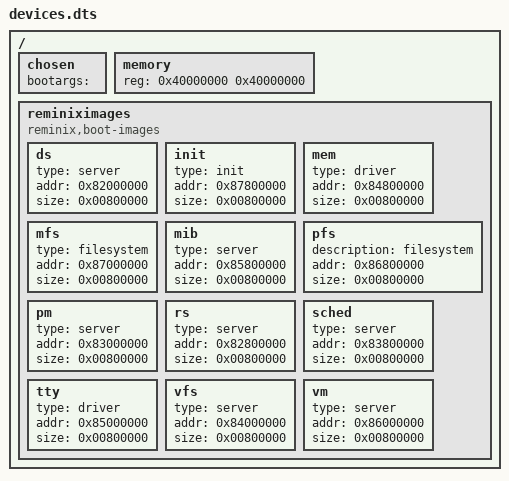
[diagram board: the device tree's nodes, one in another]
/dts-v1/;

#include "sun8i-h3-orangepi-pc-plus.dts"

/ {

	chosen {
		bootargs = "";
	};

	memory {
		device_type = "memory";
		reg = <0x40000000 0x40000000>;
	};

	reminiximages {
		compatible = "reminix,boot-images";
    		  ds {
				  type = "server";
                  addr = <0x82000000>;
                  size = <0x00800000>;
            };

    		  init {
				  type = "init";
                  addr = <0x87800000>;
                  size = <0x00800000>;
            };

    		  mem {
				  type = "driver";
                  addr = <0x84800000>;
				  size = <0x00800000>;
            };

    		  mfs {
				  type = "filesystem";
                  addr = <0x87000000>;
				  size = <0x00800000>;
            };

    		  mib {
				  type = "server";
                  addr = <0x85800000>;
				  size = <0x00800000>;
            };

    		  pfs {
            			description = "filesystem";
                  addr = <0x86800000>;
				  size = <0x00800000>;
            };

    		  pm {
				  type = "server";
                  addr = <0x83000000>;
				  size = <0x00800000>;
            };

    		  rs {
				  type = "server";
                  addr = <0x82800000>;
				  size = <0x00800000>;
            };

    		  sched {
				  type = "server";
                  addr = <0x83800000>;
				  size = <0x00800000>;
            };

    		  tty {
				  type = "driver";
                  addr = <0x85000000>;
				  size = <0x00800000>;
            };

    		  vfs {
				  type = "server";
                  addr = <0x84000000>;
				  size = <0x00800000>;
            };

    		  vm {
				  type = "server";
                  addr = <0x86000000>;
				  size = <0x00800000>;
            };

   };
};
